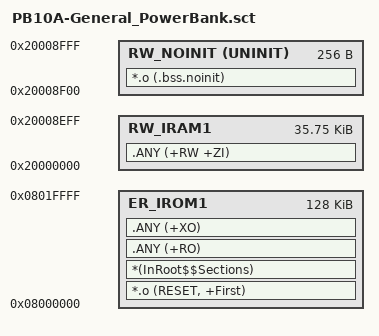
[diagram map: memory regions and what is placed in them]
; PB10A · STM32G070KBTx：Flash 128 KiB / SRAM 36 KiB。
; 仅末 256 B 为复位不清除区，供 FaultRecord(48B) + WWDG trace(16B) + SC7A20(20B) + Battery(40B) + MMC5603(16B) + Altimeter(12B) 共享。
; 软件复位保留；VDD 掉电不保留。其余 RW/ZI（含栈堆）在 RW_IRAM1。
LR_IROM1 0x08000000 0x00020000 {
  ER_IROM1 0x08000000 0x00020000 {
    *.o (RESET, +First)
    *(InRoot$$Sections)
    .ANY (+RO)
    .ANY (+XO)
  }
  RW_IRAM1 0x20000000 0x00008F00 {
    .ANY (+RW +ZI)
  }
  ; Arm Compiler 6: .bss prefix creates ZI; UNINIT skips startup zeroing.
  RW_NOINIT 0x20008F00 UNINIT 0x00000100 {
    *.o (.bss.noinit)
  }
}
